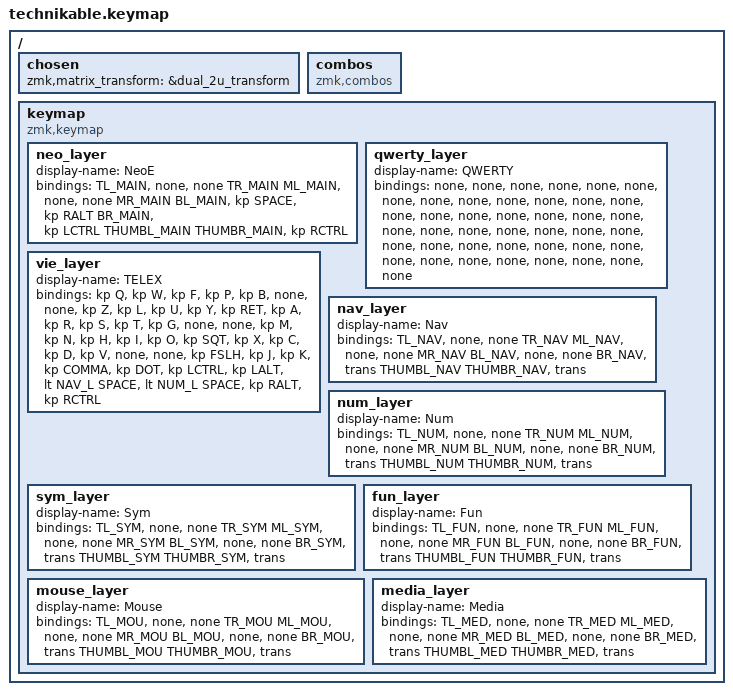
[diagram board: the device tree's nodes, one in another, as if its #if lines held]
/*
 * Copyright (c) 2022 Pete Johanson
 *
 * SPDX-License-Identifier: MIT
 */

#include <behaviors.dtsi>
/* #include <behaviors/num_word.dtsi> // requires auto-layer module */
#include <dt-bindings/zmk/keys.h>
#include <dt-bindings/zmk/bt.h>
#include <dt-bindings/zmk/outputs.h>

// #define TBLE_ORTHO   true
#define TBLE_MIT     true
//#define TBLE_DUAL_2U true

#include "zmk-helpers/helper.h"
#include "./fingers.dtsi"

#define COMBO_TIMEOUT 70
#define COMBO_LAYERS 1
#define STICKY_TIMEOUT 500

// LEFT SIDE
#define TLI 3 // TOP
#define TLM 2 // TOP
#define TLR 1 // TOP
#define TLP 0 // TOP
#define BLI 15 // BOTTOM
#define BLM 14 // BOTTOM
#define BLR 13 // BOTTOM
#define BLP 12 // BOTTOM
#define LOT 38 // O-THUMB
#define LIT 37 // I-THUMB

// RIGHT SIDE
#define TRI 8 // TOP
#define TRM 9 // TOP
#define TRR 10 // TOP
#define TRP 11 // TOP
#define BRI 20 // BOTTOM
#define BRM 21 // BOTTOM
#define BRR 22 // BOTTOM
#define BRP 23 // BOTTOM
#define ROT 40 // O-THUMB
#define RIT 41 // I-THUMB


#include "../../../merlinvn/config.dtsi"
#include "../../../merlinvn/macros.dtsi"
#include "../../../merlinvn/behaviors.dtsi"
#include "../../../merlinvn/combos.dtsi"
#include "../../../merlinvn/mouse.dtsi"
#include "../../../merlinvn/keymap.dtsi"

#define BT(n) BT_SEL n

/ {
    chosen {
       zmk,matrix_transform =
#ifdef TBLE_DUAL_2U
                       &dual_2u_transform;
#elif defined(TBLE_MIT)
                       &mit_transform;
#else
                       &ortho_transform;
#endif
    };
    combos {
      compatible = "zmk,combos";
    };
    keymap {
        compatible = "zmk,keymap";

        neo_layer {
            display-name = "NeoE";
            bindings = <
                TL_MAIN      &none &none       TR_MAIN
                ML_MAIN      &none &none       MR_MAIN
                BL_MAIN      &kp SPACE &kp RALT       BR_MAIN
#ifdef TBLE_DUAL_2U
        &kp LCTRL  THUMBL_MAIN                                THUMBR_MAIN  &kp RCTRL
#elif defined(TBLE_MIT)
       &kp LGUI   THUMBL_MAIN              &kp F1             THUMBR_MAIN  &kp RGUI
#else
       &kp LCTRL  THUMBL_MAIN     &kp SPACE    &kp SPACE      THUMBR_MAIN  &kp RCTRL
#endif
            >;
        };

        qwerty_layer {
            display-name = "QWERTY";
            bindings = <
                &none   &none  &none  &none  &none   &none    &none      &none  &none   &none   &none &none 
                &none   &none  &none  &none  &none   &none    &none      &none  &none   &none   &none &none 
                &none   &none  &none  &none  &none   &none    &none      &none  &none   &none   &none &none 
#ifdef TBLE_DUAL_2U
                       &none  &none  &none  &none  &none  &none
#elif defined(TBLE_MIT)
                       &none  &none  &none  &none  &none  &none  &none
#else
                       &none  &none  &none  &none  &none  &none  &none  &none
#endif
            >;
        };

        vie_layer {
            display-name = "TELEX";
            bindings = <
                &kp Q      &kp W     &kp F     &kp P          &kp B    &none    &none         &kp Z    &kp L  &kp U   &kp Y       &kp RET
                &kp A      &kp R     &kp S     &kp T          &kp G    &none    &none         &kp M    &kp N  &kp H   &kp I       &kp O
                &kp SQT    &kp X     &kp C     &kp D          &kp V    &none    &none         &kp FSLH &kp J  &kp K   &kp COMMA   &kp DOT
#ifdef TBLE_DUAL_2U
                       &kp LCTRL  &kp LALT      &lt NAV_L SPACE                &lt NUM_L SPACE              &kp RALT    &kp RCTRL
#elif defined(TBLE_MIT)
                       &kp LCTRL  &sl NUM_L  &lt NAV_L SPACE              &none                &lt FUN_L E  &sl SYM_L  &kp RCTRL
#else
                       &kp LCTRL  &kp LALT    &mo NAV_L      &kp SPACE      &kp SPACE        &mo NUM_L      &kp RALT    &kp RCTRL
#endif
            >;
        };

        nav_layer {
            display-name = "Nav";
            bindings = <
                TL_NAV     &none  &none      TR_NAV
                ML_NAV     &none  &none      MR_NAV
                BL_NAV     &none  &none      BR_NAV
#ifdef TBLE_DUAL_2U
                      &trans     THUMBL_NAV                           THUMBR_NAV  &trans
#elif defined(TBLE_MIT)
                      &trans     THUMBL_NAV            &trans         THUMBR_NAV   &trans
#else
                      &trans     THUMBL_NAV      &trans       &trans  THUMBR_NAV   &trans
#endif
            >;
        };

        num_layer {
            display-name = "Num";
            bindings = <
                TL_NUM      &none  &none      TR_NUM
                ML_NUM      &none  &none      MR_NUM
                BL_NUM      &none  &none      BR_NUM
#ifdef TBLE_DUAL_2U
                     &trans     THUMBL_NUM                            THUMBR_NUM   &trans
#elif defined(TBLE_MIT)
                     &trans     THUMBL_NUM           &none            THUMBR_NUM   &trans
#else
                     &trans     THUMBL_NUM    &none         &none     THUMBR_NUM   &trans
#endif
            >;
        };

        sym_layer {
            display-name = "Sym";
            bindings = <
                TL_SYM     &none   &none      TR_SYM
                ML_SYM     &none   &none      MR_SYM
                BL_SYM     &none   &none      BR_SYM
#ifdef TBLE_DUAL_2U
                      &trans  THUMBL_SYM                            THUMBR_SYM  &trans
#elif defined(TBLE_MIT)
                      &trans  THUMBL_SYM           &trans           THUMBR_SYM  &trans
#else
                      &trans  THUMBL_SYM     &trans       &trans    THUMBR_SYM  &trans
#endif
            >;
        };

        fun_layer {
            display-name = "Fun";
            bindings = <
                TL_FUN    &none  &none     TR_FUN
                ML_FUN    &none  &none     MR_FUN
                BL_FUN    &none  &none     BR_FUN
#ifdef TBLE_DUAL_2U
                      &trans    THUMBL_FUN                               THUMBR_FUN  &trans
#elif defined(TBLE_MIT)
                      &trans    THUMBL_FUN              &trans           THUMBR_FUN  &trans
#else
                      &trans    THUMBL_FUN        &trans       &trans    THUMBR_FUN  &trans
#endif
            >;
        };

        mouse_layer {
            display-name = "Mouse";
            bindings = <
                TL_MOU     &none  &none      TR_MOU
                ML_MOU     &none  &none      MR_MOU
                BL_MOU     &none  &none      BR_MOU
#ifdef TBLE_DUAL_2U
                      &trans     THUMBL_MOU                           THUMBR_MOU  &trans
#elif defined(TBLE_MIT)
                      &trans     THUMBL_MOU            &trans         THUMBR_MOU   &trans
#else
                      &trans     THUMBL_MOU      &trans       &trans  THUMBR_MOU   &trans
#endif
            >;
        };

        media_layer {
            display-name = "Media";
            bindings = <
                TL_MED     &none  &none     TR_MED
                ML_MED     &none  &none     MR_MED
                BL_MED     &none  &none     BR_MED
#ifdef TBLE_DUAL_2U
             &trans    THUMBL_MED                             THUMBR_MED  &trans
#elif defined(TBLE_MIT)
             &trans    THUMBL_MED            &trans           THUMBR_MED  &trans
#else
             &trans    THUMBL_MED      &trans       &trans    THUMBR_MED  &trans
#endif
            >;
        };

    };
};

